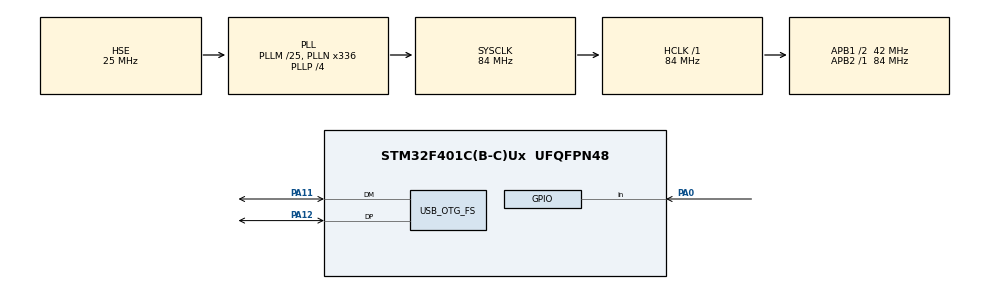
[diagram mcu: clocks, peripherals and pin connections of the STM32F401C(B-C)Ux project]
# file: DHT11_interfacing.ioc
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Mcu.Family=STM32F4
Mcu.Name=STM32F401C(B-C)Ux
Mcu.Package=UFQFPN48
NVIC.OTG_FS_IRQn=true\:0\:0\:false\:false\:true\:false\:true\:true
NVIC.PriorityGroup=NVIC_PRIORITYGROUP_4
PA0-WKUP.Signal=GPIO_Input
PA11.Mode=Device_Only
PA11.Signal=USB_OTG_FS_DM
PA12.Mode=Device_Only
PA12.Signal=USB_OTG_FS_DP
PA13.Mode=Serial_Wire
PA13.Signal=SYS_JTMS-SWDIO
PA14.Mode=Serial_Wire
PA14.Signal=SYS_JTCK-SWCLK
PC14-OSC32_IN.Mode=LSE-External-Oscillator
PC14-OSC32_IN.Signal=RCC_OSC32_IN
PC15-OSC32_OUT.Mode=LSE-External-Oscillator
PC15-OSC32_OUT.Signal=RCC_OSC32_OUT
PH0\ -\ OSC_IN.Mode=HSE-External-Oscillator
PH0\ -\ OSC_IN.Signal=RCC_OSC_IN
PH1\ -\ OSC_OUT.Mode=HSE-External-Oscillator
PH1\ -\ OSC_OUT.Signal=RCC_OSC_OUT
ProjectManager.HeapSize=0x200
ProjectManager.StackSize=0x400
ProjectManager.TargetToolchain=STM32CubeIDE
RCC.48MHZClocksFreq_Value=48000000
RCC.AHBFreq_Value=84000000
RCC.APB1CLKDivider=RCC_HCLK_DIV2
RCC.APB1Freq_Value=42000000
RCC.APB1TimFreq_Value=84000000
RCC.APB2Freq_Value=84000000
RCC.APB2TimFreq_Value=84000000
RCC.CortexFreq_Value=84000000
RCC.FLatency=FLASH_LATENCY_2
RCC.HCLKFreq_Value=84000000
RCC.HSE_VALUE=25000000
RCC.HSI_VALUE=16000000
RCC.PLLM=25
RCC.PLLN=336
RCC.PLLP=RCC_PLLP_DIV4
RCC.PLLQ=7
RCC.SYSCLKFreq_VALUE=84000000
RCC.SYSCLKSource=RCC_SYSCLKSOURCE_PLLCLK
RCC.VCOOutputFreq_Value=336000000
TIM1.AutoReloadPreload=TIM_AUTORELOAD_PRELOAD_DISABLE
TIM1.ClockDivision=TIM_CLOCKDIVISION_DIV1
TIM1.CounterMode=TIM_COUNTERMODE_UP
TIM1.Period=65535
TIM1.Prescaler=84
TIM1.RepetitionCounter=0
TIM1.TIM_MasterOutputTrigger=TIM_TRGO_RESET
TIM1.TIM_MasterSlaveMode=TIM_MASTERSLAVEMODE_DISABLE
USB_DEVICE.APP_RX_DATA_SIZE=1024
USB_DEVICE.APP_TX_DATA_SIZE=1024
USB_DEVICE.CLASS_NAME_FS=CDC
USB_DEVICE.CONFIGURATION_STRING_CDC_FS=CDC Config
USB_DEVICE.INTERFACE_STRING_CDC_FS=CDC Interface
USB_DEVICE.LANGID_STRING=1033
USB_DEVICE.MANUFACTURER_STRING=STMicroelectronics
USB_DEVICE.PID_CDC_FS=22336
USB_DEVICE.PRODUCT_STRING_CDC_FS=STM32 Virtual ComPort
USB_DEVICE.USBD_DEBUG_LEVEL=0
USB_DEVICE.USBD_MAX_NUM_CONFIGURATION=1
USB_DEVICE.USBD_MAX_NUM_INTERFACES=1
USB_DEVICE.USBD_MAX_STR_DESC_SIZ=512
USB_DEVICE.USBD_SELF_POWERED=1
USB_DEVICE.VID=1155
USB_DEVICE.VirtualMode=Cdc
USB_DEVICE.VirtualModeFS=Cdc_FS
USB_OTG_FS.Sof_enable=DISABLE
USB_OTG_FS.VirtualMode=Device_Only
USB_OTG_FS.low_power_enable=DISABLE
USB_OTG_FS.lpm_enable=DISABLE
USB_OTG_FS.vbus_sensing_enable=DISABLE
VP_TIM1_VS_ClockSourceINT.Mode=Internal
VP_USB_DEVICE_VS_USB_DEVICE_CDC_FS.Mode=CDC_FS
board=custom

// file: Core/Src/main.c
/* USER CODE BEGIN Header */
/**
  ******************************************************************************
  * @file           : main.c
  * @brief          : Main program body
  ******************************************************************************
  * @attention
  *
  * Copyright (c) 2023 STMicroelectronics.
  * All rights reserved.
  *
  * This software is licensed under terms that can be found in the LICENSE file
  * in the root directory of this software component.
  * If no LICENSE file comes with this software, it is provided AS-IS.
  *
  ******************************************************************************
  */
/* USER CODE END Header */
#include "main.h"
#include "usb_device.h"

/* USER CODE BEGIN PM */
#define read_bits(x) (1<<(7-x))
#define DHT11_PORT GPIOA
#define DHT11_PIN GPIO_PIN_0
/* USER CODE END PM */

TIM_HandleTypeDef htim1;

/* USER CODE BEGIN PV */
typedef struct sensor_values{
	uint8_t humidity_HB;
	uint8_t humidity_LB;
	uint8_t temperature_HB;
	uint8_t temperature_LB;
	uint8_t checksum;
}sensor_val;
/* USER CODE END PV */

void SystemClock_Config(void);
static void MX_TIM1_Init(void);
/* USER CODE BEGIN PFP */
void print(uint8_t val);
uint8_t binaryToDecimal(uint8_t binaryNumber);
void Set_Pin_Input(void);
void Set_Pin_Output(void);
void microsecond_delay (uint16_t us);
void Sensor_start(void);
uint8_t Sensor_response(void);
uint8_t Read_data(void);
extern uint8_t CDC_Transmit_FS(uint8_t* Buf, uint16_t Len);
void print_dht11_data(void);
/* USER CODE END PFP */

/* USER CODE BEGIN 0 */

void Set_Pin_Output(void){
   GPIO_InitTypeDef GPIO_InitStruct = {0};

  /* GPIO Ports Clock Enable */
  __HAL_RCC_GPIOC_CLK_ENABLE();
  __HAL_RCC_GPIOA_CLK_ENABLE();

  /*Configure GPIO pin Output Level */
  HAL_GPIO_WritePin(DHT11_PORT, DHT11_PIN, GPIO_PIN_RESET);

  /*Configure GPIO pin : PC13 */
  GPIO_InitStruct.Pin = DHT11_PIN;
  GPIO_InitStruct.Mode = GPIO_MODE_OUTPUT_PP;
  GPIO_InitStruct.Pull = GPIO_NOPULL;
  GPIO_InitStruct.Speed = GPIO_SPEED_FREQ_LOW;
  HAL_GPIO_Init(DHT11_PORT, &GPIO_InitStruct);
}
void Set_Pin_Input(void){
    GPIO_InitTypeDef GPIO_InitStruct = {0};
/* USER CODE BEGIN MX_GPIO_Init_1 */
/* USER CODE END MX_GPIO_Init_1 */

  /* GPIO Ports Clock Enable */
  __HAL_RCC_GPIOC_CLK_ENABLE();
  __HAL_RCC_GPIOH_CLK_ENABLE();
  __HAL_RCC_GPIOA_CLK_ENABLE();

  /*Configure GPIO pin : PA0 */
  GPIO_InitStruct.Pin = DHT11_PIN;
  GPIO_InitStruct.Mode = GPIO_MODE_INPUT;
  GPIO_InitStruct.Pull = GPIO_NOPULL;
  HAL_GPIO_Init(DHT11_PORT, &GPIO_InitStruct);
}
void print(uint8_t val)
{
	uint8_t* v =&val;
	CDC_Transmit_FS(v,sizeof(v));

}
uint8_t binaryToDecimal(uint8_t binaryNumber)
  {
    uint8_t decimalNumber = 0;
    uint8_t base = 1; // Initialize the base to 2^0

    while (binaryNumber > 0) {
        uint8_t lastBit = binaryNumber % 10; // Get the rightmost bit
        decimalNumber += lastBit * base; // Add the bit to the result
        binaryNumber = binaryNumber / 10; // Remove the rightmost bit
        base *= 2; // Update the base to the next power of 2
    }

    return decimalNumber;
  }
void microsecond_delay (uint16_t us)
{
	__HAL_TIM_SET_COUNTER(&htim1,0);  // set the counter value a 0
	while ((uint16_t)(__HAL_TIM_GET_COUNTER(&htim1)) < us);
}
void Sensor_start (void)
{
	Set_Pin_Output ();  // set the pin as output
	HAL_GPIO_WritePin (DHT11_PORT, DHT11_PIN, 0);   // pull the pin low
	microsecond_delay (18000);   // wait for 18ms
	Set_Pin_Input();    // set as input
}
uint8_t Sensor_response (void)
{
	uint8_t Response = 0;
	microsecond_delay (40);
	if (!(HAL_GPIO_ReadPin (DHT11_PORT, DHT11_PIN)))
	{
		microsecond_delay (80);
		if ((HAL_GPIO_ReadPin (DHT11_PORT, DHT11_PIN)))
			Response = 1;
		else
			Response = -1;
	}
	while ((HAL_GPIO_ReadPin (DHT11_PORT, DHT11_PIN)));   // wait for the pin to go low

	return Response;
}
uint8_t Read_data (void)
{
	uint8_t i,j;
	for (j=0;j<8;j++)
	{
		while (!(HAL_GPIO_ReadPin (DHT11_PORT, DHT11_PIN)));   // wait for the pin to go high
		microsecond_delay (40);   // wait for 40 us
		if (!(HAL_GPIO_ReadPin (DHT11_PORT, DHT11_PIN)))   // if the pin is low
		{
			i^= read_bits(j);   // write 0
		}
		else i|= read_bits(j);;  // if the pin is high, write 1
		while ((HAL_GPIO_ReadPin (DHT11_PORT, DHT11_PIN)));  // wait for the pin to go low
	}
	return i;
}
void print_dht11_data(void)
{	uint8_t sum;
	uint8_t buffer[] = "error";
	sensor_val dht11;
	Sensor_start();
	if (Sensor_response>0)
	{
		dht11.humidity_HB = Read_data();
		dht11.humidity_LB = Read_data();
		dht11.temperature_HB = Read_data();
		dht11.temperature_LB = Read_data();
		dht11.checksum = Read_data();
		sum = dht11.humidity_HB+dht11.humidity_LB+dht11.temperature_HB+dht11.temperature_LB;
		if (sum == dht11.checksum)
		{

			dht11.humidity_HB = binaryToDecimal(dht11.humidity_HB);
			dht11.temperature_HB = binaryToDecimal(dht11.temperature_HB );
			print(dht11.humidity_HB);
			print(dht11.temperature_HB);

		}
		else
			CDC_Transmit_FS(buffer,sizeof(buffer));
	}

}
/* USER CODE END 0 */

int main(void)
{
  /* USER CODE BEGIN 1 */
  HAL_TIM_Base_Start(&htim1);

  /* USER CODE END 1 */

  /* MCU Configuration--------------------------------------------------------*/

  /* Reset of all peripherals, Initializes the Flash interface and the Systick. */
  HAL_Init();

  /* Configure the system clock */
  SystemClock_Config();

  /* Initialize all configured peripherals */
  MX_TIM1_Init();
  MX_USB_DEVICE_Init();

  /* Infinite loop */
  while (1)
  {
	  print_dht11_data();
	  HAL_Delay(1000);
  }
}

void SystemClock_Config(void)
{
  RCC_OscInitTypeDef RCC_OscInitStruct = {0};
  RCC_ClkInitTypeDef RCC_ClkInitStruct = {0};

  /** Configure the main internal regulator output voltage
  */
  __HAL_RCC_PWR_CLK_ENABLE();
  __HAL_PWR_VOLTAGESCALING_CONFIG(PWR_REGULATOR_VOLTAGE_SCALE2);

  /** Initializes the RCC Oscillators according to the specified parameters
  * in the RCC_OscInitTypeDef structure.
  */
  RCC_OscInitStruct.OscillatorType = RCC_OSCILLATORTYPE_HSE;
  RCC_OscInitStruct.HSEState = RCC_HSE_ON;
  RCC_OscInitStruct.PLL.PLLState = RCC_PLL_ON;
  RCC_OscInitStruct.PLL.PLLSource = RCC_PLLSOURCE_HSE;
  RCC_OscInitStruct.PLL.PLLM = 25;
  RCC_OscInitStruct.PLL.PLLN = 336;
  RCC_OscInitStruct.PLL.PLLP = RCC_PLLP_DIV4;
  RCC_OscInitStruct.PLL.PLLQ = 7;
  if (HAL_RCC_OscConfig(&RCC_OscInitStruct) != HAL_OK)
  {
    Error_Handler();
  }

  /** Initializes the CPU, AHB and APB buses clocks
  */
  RCC_ClkInitStruct.ClockType = RCC_CLOCKTYPE_HCLK|RCC_CLOCKTYPE_SYSCLK
                              |RCC_CLOCKTYPE_PCLK1|RCC_CLOCKTYPE_PCLK2;
  RCC_ClkInitStruct.SYSCLKSource = RCC_SYSCLKSOURCE_PLLCLK;
  RCC_ClkInitStruct.AHBCLKDivider = RCC_SYSCLK_DIV1;
  RCC_ClkInitStruct.APB1CLKDivider = RCC_HCLK_DIV2;
  RCC_ClkInitStruct.APB2CLKDivider = RCC_HCLK_DIV1;

  if (HAL_RCC_ClockConfig(&RCC_ClkInitStruct, FLASH_LATENCY_2) != HAL_OK)
  {
    Error_Handler();
  }
}

static void MX_TIM1_Init(void)
{

  TIM_ClockConfigTypeDef sClockSourceConfig = {0};
  TIM_MasterConfigTypeDef sMasterConfig = {0};

  htim1.Instance = TIM1;
  htim1.Init.Prescaler = 84;
  htim1.Init.CounterMode = TIM_COUNTERMODE_UP;
  htim1.Init.Period = 65535;
  htim1.Init.ClockDivision = TIM_CLOCKDIVISION_DIV1;
  htim1.Init.RepetitionCounter = 0;
  htim1.Init.AutoReloadPreload = TIM_AUTORELOAD_PRELOAD_DISABLE;
  if (HAL_TIM_Base_Init(&htim1) != HAL_OK)
  {
    Error_Handler();
  }
  sClockSourceConfig.ClockSource = TIM_CLOCKSOURCE_INTERNAL;
  if (HAL_TIM_ConfigClockSource(&htim1, &sClockSourceConfig) != HAL_OK)
  {
    Error_Handler();
  }
  sMasterConfig.MasterOutputTrigger = TIM_TRGO_RESET;
  sMasterConfig.MasterSlaveMode = TIM_MASTERSLAVEMODE_DISABLE;
  if (HAL_TIMEx_MasterConfigSynchronization(&htim1, &sMasterConfig) != HAL_OK)
  {
    Error_Handler();
  }

}

void Error_Handler(void)
{
  __disable_irq();
  while (1)
  {
  }
}
